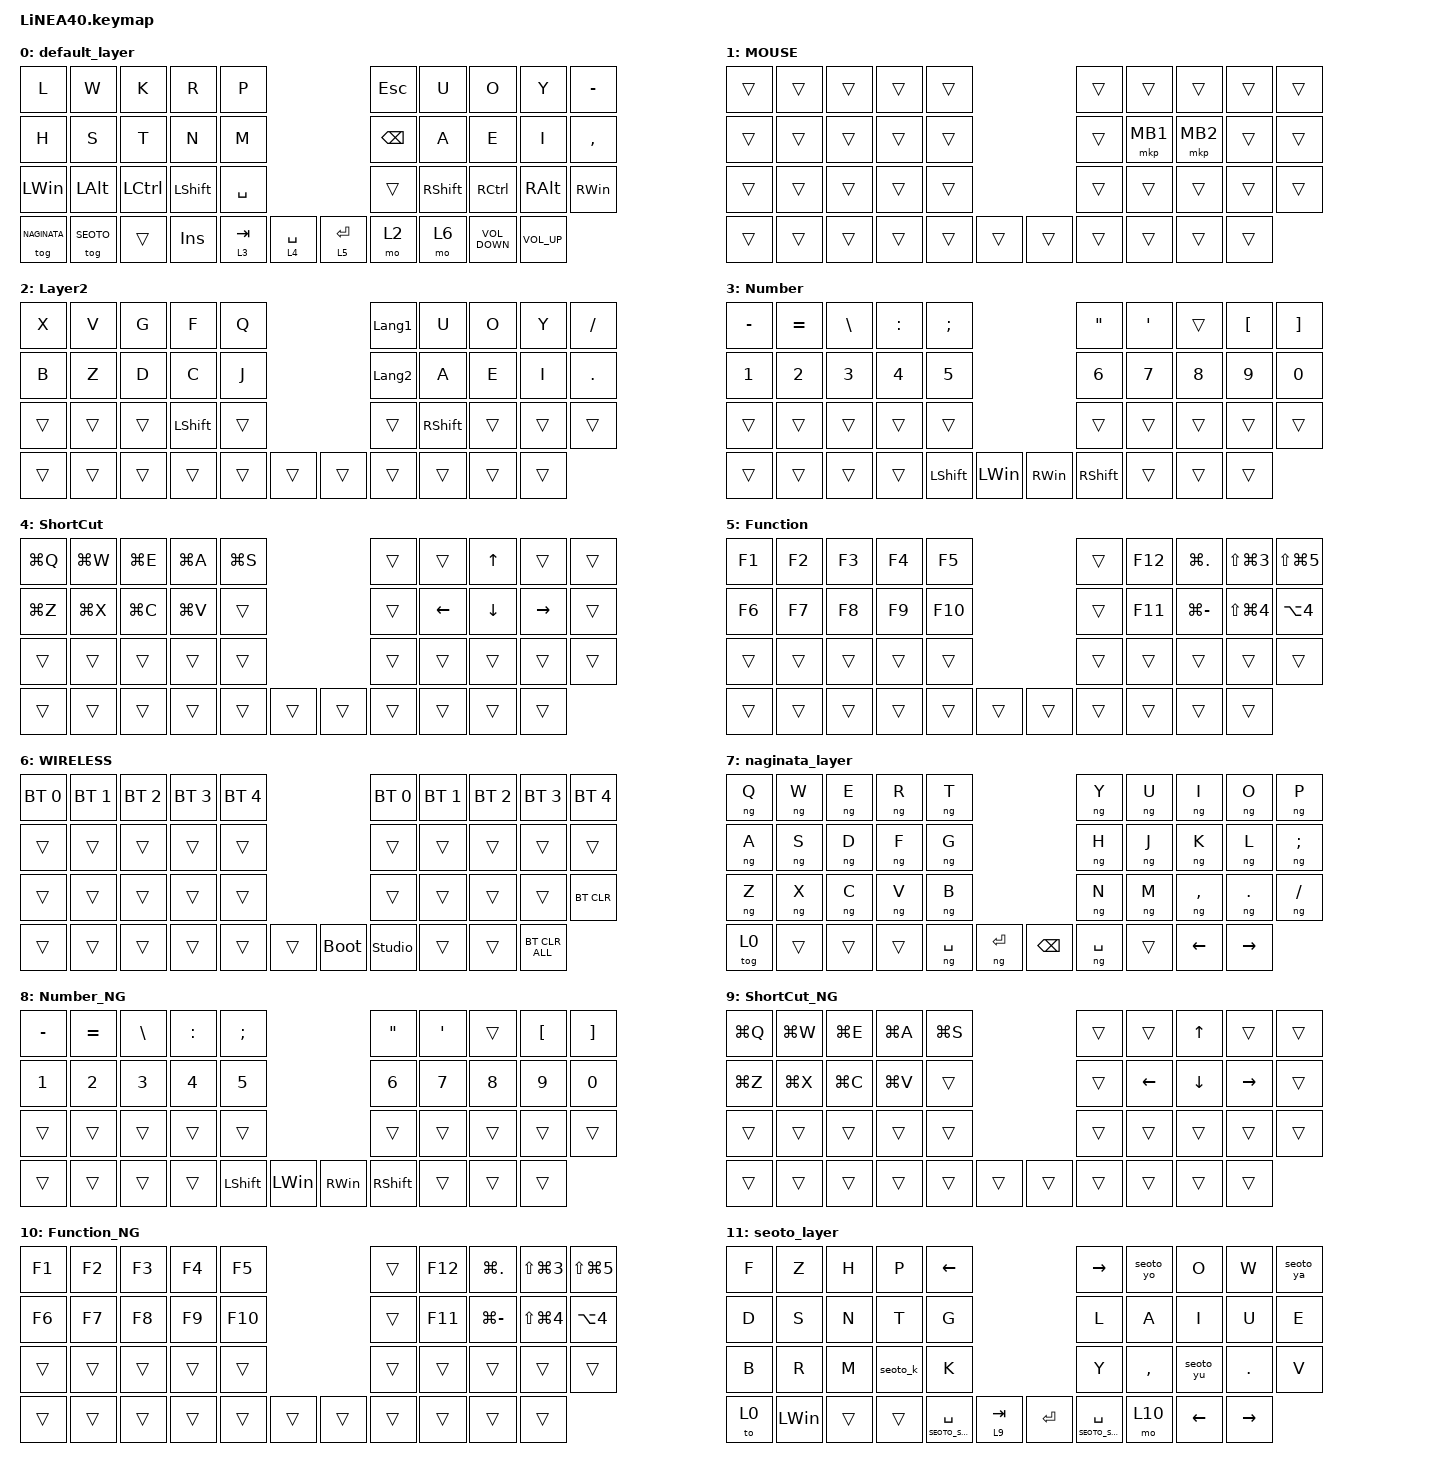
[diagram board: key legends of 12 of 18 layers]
#define ZMK_POINTING_DEFAULT_SCRL_VAL 150

#include <dt-bindings/zmk/input_transform.h>
#include <input/processors.dtsi>
#include <zephyr/dt-bindings/input/input-event-codes.h>
#include <behaviors.dtsi>
#include <dt-bindings/zmk/bt.h>
#include <dt-bindings/zmk/keys.h>
#include <dt-bindings/zmk/pointing.h>
#include <behaviors/naginata.dtsi>

#define MOUSE 1
#define MARK 2
#define CURSOR 3
#define FUNCTION 4
#define SCROLL 5
#define WIRELESS 6
#define NAGINATA 7
#define SEOTO 11
#define SEOTO_SHIFT 12
#define SEOTO_EN 13

//mouse cursol

&mmv {
    delay-ms = <20>;
    trigger-period-ms = <5>;
    time-to-max-speed-ms = <100>;
    acceleration-exponent = <2>;
};

//mouse scroll

&msc {
    delay-ms = <3>;
    trigger-period-ms = <3>;
    time-to-max-speed-ms = <100>;
    acceleration-exponent = <0>;
};

/ {
    input_processors {
        zip_wheel_scaler: zip_wheel_scaler {
            compatible = "zmk,input-processor-scaler";
            #input-processor-cells = <2>;
            type = <INPUT_EV_REL>;
            codes = <INPUT_REL_WHEEL>;
            track-remainders;
        };
    };
};

&msc_input_listener {
    speed_up {
        layers = <FUNCTION>;
        input-processors = <&zip_wheel_scaler 3 1>; //スクロールを3倍速にする
    };
};

&trackball_listener {
    scroller {
        layers = <SCROLL>;
        input-processors =
            <&zip_xy_transform INPUT_TRANSFORM_Y_INVERT>,
            //スクロール方向を逆転,,
            <&zip_xy_to_scroll_mapper>;
    };
};

/ {
    macros {
        ng_on: ng_on {
            compatible = "zmk,behavior-macro";
            #binding-cells = <0>;
            bindings = <&macro_tap &kp LANGUAGE_1 &kp INTERNATIONAL_4 &to NAGINATA>;
        };

        ng_off: ng_off {
            compatible = "zmk,behavior-macro";
            #binding-cells = <0>;
            bindings = <&macro_tap &kp LANGUAGE_2 &kp INTERNATIONAL_5 &to 0>;
        };

        seoto_nn: seoto_nn {
            compatible = "zmk,behavior-macro";
            #binding-cells = <0>;
            bindings = <&macro_tap &kp N &kp N>;
        };

        seoto_xtu: seoto_xtu {
            compatible = "zmk,behavior-macro";
            #binding-cells = <0>;
            bindings = <&macro_tap &kp X &kp T &kp U>;
        };

        seoto_k: seoto_k {
            compatible = "zmk,behavior-macro";
            #binding-cells = <0>;
            bindings = <&macro_tap &kp K>;
        };

        seoto_ya: seoto_ya {
            compatible = "zmk,behavior-macro";
            #binding-cells = <0>;
            bindings = <&macro_tap &kp Y &kp A>;
        };

        seoto_yu: seoto_yu {
            compatible = "zmk,behavior-macro";
            #binding-cells = <0>;
            bindings = <&macro_tap &kp Y &kp U>;
        };

        seoto_yo: seoto_yo {
            compatible = "zmk,behavior-macro";
            #binding-cells = <0>;
            bindings = <&macro_tap &kp Y &kp O>;
        };

        seoto_lang1: seoto_lang1 {
            compatible = "zmk,behavior-macro";
            #binding-cells = <0>;
            bindings = <&macro_tap &kp LANGUAGE_1 &to SEOTO>;
        };

        seoto_lang2: seoto_lang2 {
            compatible = "zmk,behavior-macro";
            #binding-cells = <0>;
            bindings = <&macro_tap &kp LANGUAGE_2 &to SEOTO_EN>;
        };
    };

    combos {
        compatible = "zmk,combos";

        combo_ng_on {
            timeout-ms = <300>;
            key-positions = <15 16>;
            bindings = <&ng_on>;
            layers = <0>;
        };

        combo_ng_off {
            timeout-ms = <300>;
            key-positions = <13 14>;
            bindings = <&ng_off>;
            layers = <0 NAGINATA>;
        };

        ZenkakuHankaku {
            bindings = <&kp GRAVE>;
            key-positions = <11 12>;
        };

        DeleteKey {
            bindings = <&kp DEL>;
            key-positions = <7 8>;
        };

        InsertKey {
            bindings = <&kp INS>;
            key-positions = <6 7>;
        };

        CenterClick {
            bindings = <&mkp MB3>;
            key-positions = <17 16>;
        };

        RightClick {
            bindings = <&mkp MB2>;
            key-positions = <18 17>;
        };

        PrevClick {
            bindings = <&mkp MB4>;
            key-positions = <27 28>;
        };

        ClickNext {
            bindings = <&mkp MB5>;
            key-positions = <26 27>;
        };
    };

    behaviors {
        re_kp: sensor_rotate_kp {
            compatible = "zmk,behavior-sensor-rotate-var";
            #sensor-binding-cells = <2>;
            bindings = <&kp>, <&kp>;
        };

        mouse_scrl: mouse_wheel_scrl {
            compatible = "zmk,behavior-sensor-rotate-var";
            #sensor-binding-cells = <2>;
            bindings = <&msc>, <&msc>;

            tap-ms = <20>;
        };
    };

    keymap {
        compatible = "zmk,keymap";

        default_layer {
            bindings = <
&kp L         &kp W         &kp K      &kp R           &kp P                                  &kp ESC   &kp U            &kp O      &kp Y              &kp MINUS
&kp H         &kp S         &kp T      &kp N           &kp M                                  &kp BSPC  &kp A            &kp E      &kp I              &kp COMMA
&kp LEFT_WIN  &kp LEFT_ALT  &kp LCTRL  &kp LEFT_SHIFT  &kp SPACE                              &trans    &kp RIGHT_SHIFT  &kp RCTRL  &kp RIGHT_ALT      &kp RIGHT_WIN
&tog NAGINATA &tog SEOTO    &trans     &kp INS         &lt 3 TAB  &lt 4 SPACE    &lt 5 ENTER  &mo 2                      &mo 6      &kp C_VOLUME_DOWN  &kp C_VOLUME_UP
            >;

            sensor-bindings = <&mouse_scrl SCRL_DOWN SCRL_UP>;
        };

        //1

        MOUSE {
            bindings = <
&trans  &trans  &trans  &trans  &trans                    &trans  &trans    &trans    &trans  &trans
&trans  &trans  &trans  &trans  &trans                    &trans  &mkp MB1  &mkp MB2  &trans  &trans
&trans  &trans  &trans  &trans  &trans                    &trans  &trans    &trans    &trans  &trans
&trans  &trans  &trans  &trans  &trans  &trans    &trans  &trans            &trans    &trans  &trans
            >;
        };

        //2

        Layer2 {
            bindings = <
&kp X   &kp V   &kp G   &kp F           &kp Q                     &kp LANGUAGE_1  &kp U            &kp O   &kp Y   &kp FSLH
&kp B   &kp Z   &kp D   &kp C           &kp J                     &kp LANGUAGE_2  &kp A            &kp E   &kp I   &kp DOT
&trans  &trans  &trans  &kp LEFT_SHIFT  &trans                    &trans          &kp RIGHT_SHIFT  &trans  &trans  &trans
&trans  &trans  &trans  &trans          &trans  &trans    &trans  &trans                           &trans  &trans  &trans
            >;

            sensor-bindings = <&re_kp C_VOLUME_DOWN C_VOLUME_UP>;
        };

        //3

        Number {
            bindings = <
&kp MINUS  &kp EQUAL  &kp BSLH  &kp COLON  &kp SEMI                                       &kp DQT          &kp APOS  &trans  &kp LBKT  &kp RBKT
&kp N1     &kp N2     &kp N3    &kp N4     &kp N5                                         &kp N6           &kp N7    &kp N8  &kp N9    &kp N0
&trans     &trans     &trans    &trans     &trans                                         &trans           &trans    &trans  &trans    &trans
&trans     &trans     &trans    &trans     &kp LEFT_SHIFT  &kp LEFT_WIN    &kp RIGHT_WIN  &kp RIGHT_SHIFT            &trans  &trans    &trans
            >;
        };

        //4

        ShortCut {
            bindings = <
&kp LG(Q)  &kp LG(W)  &kp LG(E)  &kp LG(A)  &kp LG(S)                    &trans  &trans          &kp UP_ARROW    &trans           &trans
&kp LG(Z)  &kp LG(X)  &kp LG(C)  &kp LG(V)  &trans                       &trans  &kp LEFT_ARROW  &kp DOWN_ARROW  &kp RIGHT_ARROW  &trans
&trans     &trans     &trans     &trans     &trans                       &trans  &trans          &trans          &trans           &trans
&trans     &trans     &trans     &trans     &trans     &trans    &trans  &trans                  &trans          &trans           &trans
            >;

            sensor-bindings = <&mouse_scrl SCRL_DOWN SCRL_UP>;
        };

        //5

        Function {
            bindings = <
&kp F1  &kp F2  &kp F3  &kp F4  &kp F5                     &trans  &kp F12  &kp LG(DOT)    &kp LS(LG(NUMBER_3))  &kp LS(LG(N5))
&kp F6  &kp F7  &kp F8  &kp F9  &kp F10                    &trans  &kp F11  &kp LG(MINUS)  &kp LS(LG(NUMBER_4))  &kp LA(NUMBER_4)
&trans  &trans  &trans  &trans  &trans                     &trans  &trans   &trans         &trans                &trans
&trans  &trans  &trans  &trans  &trans   &trans    &trans  &trans           &trans         &trans                &trans
            >;

            sensor-bindings = <&inc_dec_kp DOWN_ARROW UP_ARROW>;
        };

        //6

        WIRELESS {
            bindings = <
&bt BT_SEL 0  &bt BT_SEL 1  &bt BT_SEL 2  &bt BT_SEL 3  &bt BT_SEL 4                         &bt BT_SEL 0    &bt BT_SEL 1  &bt BT_SEL 2  &bt BT_SEL 3  &bt BT_SEL 4
&trans        &trans        &trans        &trans        &trans                               &trans          &trans        &trans        &trans        &trans
&trans        &trans        &trans        &trans        &trans                               &trans          &trans        &trans        &trans        &bt BT_CLR
&trans        &trans        &trans        &trans        &trans        &trans    &bootloader  &studio_unlock                &trans        &trans        &bt BT_CLR_ALL
            >;

            sensor-bindings = <&inc_dec_kp RIGHT_ARROW LEFT_ARROW>;
        };

        //7 — 薙刀式（QWERTY物理位置。親指は調整済みレイアウト）

        naginata_layer {
            bindings = <
&ng Q         &ng W         &ng E      &ng R           &ng T                                  &ng Y     &ng U            &ng I      &ng O              &ng P
&ng A         &ng S         &ng D      &ng F           &ng G                                  &ng H     &ng J            &ng K      &ng L              &ng SEMI
&ng Z         &ng X         &ng C      &ng V           &ng B                                  &ng N     &ng M            &ng COMMA  &ng DOT           &ng SLASH
&tog 0        &trans        &trans     &trans          &ng SPACE  &ng ENTER    &kp BACKSPACE  &ng SPACE                  &trans     &kp LEFT_ARROW     &kp RIGHT_ARROW
            >;

            sensor-bindings = <&mouse_scrl SCRL_DOWN SCRL_UP>;
        };

        //8 — Number copy for NAGINATA

        Number_NG {
            bindings = <
&kp MINUS  &kp EQUAL  &kp BSLH  &kp COLON  &kp SEMI                                       &kp DQT          &kp APOS  &trans  &kp LBKT  &kp RBKT
&kp N1     &kp N2     &kp N3    &kp N4     &kp N5                                         &kp N6           &kp N7    &kp N8  &kp N9    &kp N0
&trans     &trans     &trans    &trans     &trans                                         &trans           &trans    &trans  &trans    &trans
&trans     &trans     &trans    &trans     &kp LEFT_SHIFT  &kp LEFT_WIN    &kp RIGHT_WIN  &kp RIGHT_SHIFT            &trans  &trans    &trans
            >;
        };

        //9 — ShortCut copy for NAGINATA

        ShortCut_NG {
            bindings = <
&kp LG(Q)  &kp LG(W)  &kp LG(E)  &kp LG(A)  &kp LG(S)                    &trans  &trans          &kp UP_ARROW    &trans           &trans
&kp LG(Z)  &kp LG(X)  &kp LG(C)  &kp LG(V)  &trans                       &trans  &kp LEFT_ARROW  &kp DOWN_ARROW  &kp RIGHT_ARROW  &trans
&trans     &trans     &trans     &trans     &trans                       &trans  &trans          &trans          &trans           &trans
&trans     &trans     &trans     &trans     &trans     &trans    &trans  &trans                  &trans          &trans           &trans
            >;

            sensor-bindings = <&mouse_scrl SCRL_DOWN SCRL_UP>;
        };

        //10 — Function copy for NAGINATA

        Function_NG {
            bindings = <
&kp F1  &kp F2  &kp F3  &kp F4  &kp F5                     &trans  &kp F12  &kp LG(DOT)    &kp LS(LG(NUMBER_3))  &kp LS(LG(N5))
&kp F6  &kp F7  &kp F8  &kp F9  &kp F10                    &trans  &kp F11  &kp LG(MINUS)  &kp LS(LG(NUMBER_4))  &kp LA(NUMBER_4)
&trans  &trans  &trans  &trans  &trans                     &trans  &trans   &trans         &trans                &trans
&trans  &trans  &trans  &trans  &trans   &trans    &trans  &trans           &trans         &trans                &trans
            >;

            sensor-bindings = <&inc_dec_kp DOWN_ARROW UP_ARROW>;
        };

        //11 — せおと配列（ローマ字入力用。C=K, X=YA, J=YU, Q=YO をキーボード側で送出）

        seoto_layer {
            bindings = <
&kp F   &kp Z         &kp H   &kp P   &kp LEFT_ARROW                           &kp RIGHT_ARROW  &seoto_yo &kp O       &kp W          &seoto_ya
&kp D   &kp S         &kp N   &kp T   &kp G                                    &kp L            &kp A     &kp I      &kp U         &kp E
&kp B   &kp R         &kp M   &seoto_k &kp K                                   &kp Y            &kp COMMA &seoto_yu  &kp DOT       &kp V
&to 0   &kp LEFT_WIN  &trans  &trans  &lt SEOTO_SHIFT SPACE  &lt 9 TAB    &kp ENTER        &lt SEOTO_SHIFT SPACE        &mo 10     &kp LEFT_ARROW  &kp RIGHT_ARROW
            >;

            sensor-bindings = <&mouse_scrl SCRL_DOWN SCRL_UP>;
        };

        //12 — せおと配列 Space 長押し面（右上小文字の裏入力）

        seoto_shift_layer {
            bindings = <
&trans  &trans  &trans  &trans  &trans                                      &seoto_lang1  &seoto_lang2  &trans     &kp LS(GRAVE)  &trans
&trans  &trans  &trans  &trans  &trans                                      &kp APOS &kp BSPC &seoto_nn &kp MINUS      &seoto_xtu
&trans  &trans  &trans  &trans  &trans                                      &trans  &trans  &trans     &trans         &trans
&trans  &trans  &trans  &trans  &trans  &trans    &trans                   &trans          &trans     &trans         &trans
            >;

            sensor-bindings = <&mouse_scrl SCRL_DOWN SCRL_UP>;
        };

        //13 — せおと配列 英字入力用（C/Q/X/J をそのまま送出）

        seoto_en_layer {
            bindings = <
&kp F   &kp Z         &kp H   &kp P  &kp LEFT_ARROW                           &kp RIGHT_ARROW  &kp Q     &kp O       &kp W      &kp X
&kp D   &kp S         &kp N   &kp T  &kp G                                    &kp L            &kp A     &kp I       &kp U      &kp E
&kp B   &kp R         &kp M   &kp C  &kp K                                    &kp Y            &kp COMMA &kp J       &kp DOT    &kp V
&to 0   &kp LEFT_WIN  &trans  &trans &lt SEOTO_SHIFT SPACE  &lt 9 TAB    &kp ENTER        &lt SEOTO_SHIFT SPACE        &mo 10     &kp LEFT_ARROW  &kp RIGHT_ARROW
            >;

            sensor-bindings = <&mouse_scrl SCRL_DOWN SCRL_UP>;
        };

        //14 — Reserved to keep copied layers at 15-17

        Reserved_14 {
            bindings = <
&trans  &trans  &trans  &trans  &trans                    &trans  &trans  &trans  &trans  &trans
&trans  &trans  &trans  &trans  &trans                    &trans  &trans  &trans  &trans  &trans
&trans  &trans  &trans  &trans  &trans                    &trans  &trans  &trans  &trans  &trans
&trans  &trans  &trans  &trans  &trans  &trans    &trans  &trans          &trans  &trans  &trans
            >;
        };

        //15 — Layer 9 copy

        Layer_9_Copy {
            bindings = <
&kp LG(Q)  &kp LG(W)  &kp LG(E)  &kp LG(A)  &kp LG(S)                    &trans  &trans          &kp UP_ARROW    &trans           &trans
&kp LG(Z)  &kp LG(X)  &kp LG(C)  &kp LG(V)  &trans                       &trans  &kp LEFT_ARROW  &kp DOWN_ARROW  &kp RIGHT_ARROW  &trans
&trans     &trans     &trans     &trans     &trans                       &trans  &trans          &trans          &trans           &trans
&trans     &trans     &trans     &trans     &trans     &trans    &trans  &trans                  &trans          &trans           &trans
            >;

            sensor-bindings = <&mouse_scrl SCRL_DOWN SCRL_UP>;
        };

        //16 — Layer 10 copy

        Layer_10_Copy {
            bindings = <
&kp F1  &kp F2  &kp F3  &kp F4  &kp F5                     &trans  &kp F12  &kp LG(DOT)    &kp LS(LG(NUMBER_3))  &kp LS(LG(N5))
&kp F6  &kp F7  &kp F8  &kp F9  &kp F10                    &trans  &kp F11  &kp LG(MINUS)  &kp LS(LG(NUMBER_4))  &kp LA(NUMBER_4)
&trans  &trans  &trans  &trans  &trans                     &trans  &trans   &trans         &trans                &trans
&trans  &trans  &trans  &trans  &trans   &trans    &trans  &trans           &trans         &trans                &trans
            >;

            sensor-bindings = <&inc_dec_kp DOWN_ARROW UP_ARROW>;
        };

        //17 — Layer 11 copy

        Layer_11_Copy {
            bindings = <
&kp F   &kp Z         &kp H   &kp P   &kp LEFT_ARROW                           &kp RIGHT_ARROW  &seoto_yo &kp O       &kp W          &seoto_ya
&kp D   &kp S         &kp N   &kp T   &kp G                                    &kp L            &kp A     &kp I      &kp U         &kp E
&kp B   &kp R         &kp M   &seoto_k &kp K                                   &kp Y            &kp COMMA &seoto_yu  &kp DOT       &kp V
&to 0   &kp LEFT_WIN  &trans  &trans  &lt SEOTO_SHIFT SPACE  &lt 9 TAB    &kp ENTER        &lt SEOTO_SHIFT SPACE        &mo 10     &kp LEFT_ARROW  &kp RIGHT_ARROW
            >;

            sensor-bindings = <&mouse_scrl SCRL_DOWN SCRL_UP>;
        };
    };
};
